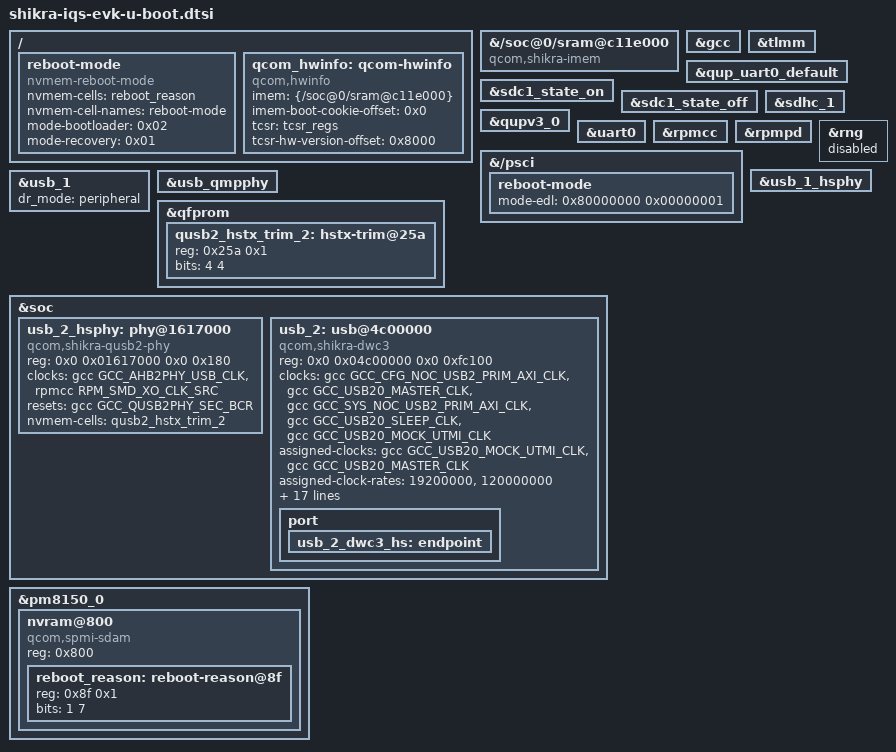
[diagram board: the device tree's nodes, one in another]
// SPDX-License-Identifier: BSD-3-Clause
/*
 * Copyright (c) Qualcomm Technologies, Inc. and/or its subsidiaries.
 */

/ {
	reboot-mode {
		compatible = "nvmem-reboot-mode";
		nvmem-cells = <&reboot_reason>;
		nvmem-cell-names = "reboot-mode";

		mode-bootloader = <0x02>;
		mode-recovery   = <0x01>;
	};

	qcom_hwinfo: qcom-hwinfo {
		compatible = "qcom,hwinfo";

		imem = <&{/soc@0/sram@c11e000}>;
		imem-boot-cookie-offset = <0x0>;

		tcsr = <&tcsr_regs>;
		tcsr-hw-version-offset = <0x8000>;
	};
};

&{/soc@0/sram@c11e000} {
	compatible = "qcom,shikra-imem", "syscon", "simple-mfd";
};

/* Keep the console and QUPFW storage paths in the SPL device tree. */
&gcc {
	bootph-all;
};

&tlmm {
	bootph-all;
};

&qup_uart0_default {
	bootph-all;
};

&sdc1_state_on {
	bootph-all;
};

&sdc1_state_off {
	bootph-all;
};

&sdhc_1 {
	bootph-all;
};

&qupv3_0 {
	bootph-all;
};

&uart0 {
	bootph-all;
};

/* Retain the RPM clock and power-domain providers for boot consumers. */
&rpmcc {
	bootph-all;
};

&rpmpd {
	bootph-all;
};

/* Enter Qualcomm EDL/download mode via "reset -edl". */
&{/psci} {
	reboot-mode {
		mode-edl = <0x80000000 0x00000001>;
	};
};

&rng {
	status = "disabled";
};

&usb_1_hsphy {
	status = "okay";
};

&usb_1 {
	dr_mode = "peripheral";

	status = "okay";
};

&usb_qmpphy {
	status = "okay";
};

/*
 * usb_2 is not in the shared Shikra U-Boot DT. Run it as a host directly;
 * usb_1 stays a peripheral for fastboot.
 */
&qfprom {
	qusb2_hstx_trim_2: hstx-trim@25a {
		reg = <0x25a 0x1>;
		bits = <4 4>;
	};
};

&soc {
	usb_2_hsphy: phy@1617000 {
		compatible = "qcom,shikra-qusb2-phy";
		reg = <0x0 0x01617000 0x0 0x180>;

		clocks = <&gcc GCC_AHB2PHY_USB_CLK>,
			 <&rpmcc RPM_SMD_XO_CLK_SRC>;
		clock-names = "cfg_ahb", "ref";

		resets = <&gcc GCC_QUSB2PHY_SEC_BCR>;
		nvmem-cells = <&qusb2_hstx_trim_2>;
		#phy-cells = <0>;

		status = "okay";
	};

	usb_2: usb@4c00000 {
		compatible = "qcom,shikra-dwc3", "qcom,snps-dwc3";
		reg = <0x0 0x04c00000 0x0 0xfc100>;

		clocks = <&gcc GCC_CFG_NOC_USB2_PRIM_AXI_CLK>,
			 <&gcc GCC_USB20_MASTER_CLK>,
			 <&gcc GCC_SYS_NOC_USB2_PRIM_AXI_CLK>,
			 <&gcc GCC_USB20_SLEEP_CLK>,
			 <&gcc GCC_USB20_MOCK_UTMI_CLK>;
		clock-names = "cfg_noc",
			      "core",
			      "iface",
			      "sleep",
			      "mock_utmi";

		assigned-clocks = <&gcc GCC_USB20_MOCK_UTMI_CLK>,
				  <&gcc GCC_USB20_MASTER_CLK>;
		assigned-clock-rates = <19200000>, <120000000>;

		interrupts-extended = <&intc GIC_SPI 507 IRQ_TYPE_LEVEL_HIGH 0>,
				      <&intc GIC_SPI 509 IRQ_TYPE_LEVEL_HIGH 0>,
				      <&intc GIC_SPI 508 IRQ_TYPE_LEVEL_HIGH 0>;
		interrupt-names = "dwc_usb3",
				  "pwr_event",
				  "hs_phy_irq";

		iommus = <&apps_smmu 0x140 0x0>;

		maximum-speed = "high-speed";

		phys = <&usb_2_hsphy>;
		phy-names = "usb2-phy";

		power-domains = <&gcc GCC_USB20_GDSC>;

		qcom,select-utmi-as-pipe-clk;
		resets = <&gcc GCC_USB20_BCR>;

		snps,dis_u2_susphy_quirk;
		snps,dis_enblslpm_quirk;
		snps,has-lpm-erratum;
		snps,hird-threshold = /bits/ 8 <0x10>;

		dr_mode = "host";
		usb-role-switch;
		wakeup-source;

		status = "okay";

		port {
			usb_2_dwc3_hs: endpoint {
			};
		};
	};
};

&pm8150_0 {
	/* Virtual NVMEM node for PON-based reboot reason storage */
	nvram@800 {
		compatible = "qcom,spmi-sdam";
		reg = <0x800>;
		#address-cells = <1>;
		#size-cells = <1>;
		ranges = <0x00 0x800 0x100>;

		/* Reboot reason cell at PON_SOFT_RB_SPARE (0x88F) */
		reboot_reason: reboot-reason@8f {
			reg = <0x8f 0x1>;
			bits = <1 7>;
		};
	};
};
